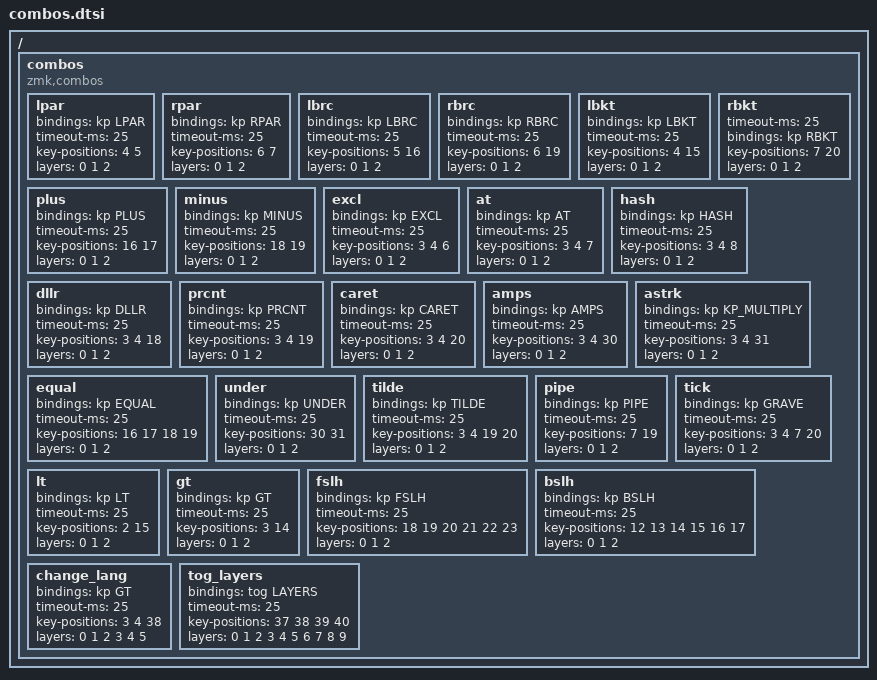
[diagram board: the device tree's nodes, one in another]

/ {
  combos {
    compatible = "zmk,combos";

    /* Basic combos */
    lpar {
      bindings = <&kp LPAR>;
      timeout-ms = <25>;
      key-positions = <4 5>;
      layers = <0 1 2>;
    };

    rpar {
      bindings = <&kp RPAR>;
      timeout-ms = <25>;
      key-positions = <6 7>;
      layers = <0 1 2>;
    };

    lbrc {
      bindings = <&kp LBRC>;
      timeout-ms = <25>;
      key-positions = <5 16>;
      layers = <0 1 2>;
    };

    rbrc {
      bindings = <&kp RBRC>;
      timeout-ms = <25>;
      key-positions = <6 19>;
      layers = <0 1 2>;
    };

    lbkt {
      bindings = <&kp LBKT>;
      timeout-ms = <25>;
      key-positions = <4 15>;
      layers = <0 1 2>;
    };

    rbkt {
      timeout-ms = <25>;
      bindings = <&kp RBKT>;
      key-positions = <7 20>;
      layers = <0 1 2>;
    };

    plus  {
      bindings = <&kp PLUS>;
      timeout-ms = <25>;
      key-positions = <16 17>;
      layers = <0 1 2>;
    };

    minus {
      bindings = <&kp MINUS>;
      timeout-ms = <25>;
      key-positions = <18 19>;
      layers = <0 1 2>;

    };

    excl  {
      bindings = <&kp EXCL>;
      timeout-ms = <25>;
      key-positions = <3 4 6>;
      layers = <0 1 2>;
    };

    at    {
      bindings = <&kp AT>;
      timeout-ms = <25>;
      key-positions = <3 4 7>;
      layers = <0 1 2>;
    };

    hash  {
      bindings = <&kp HASH>;
      timeout-ms = <25>;
      key-positions = <3 4 8>;
      layers = <0 1 2>;
    };

    dllr  {
      bindings = <&kp DLLR>;
      timeout-ms = <25>;
      key-positions = <3 4 18>;
      layers = <0 1 2>;
    };

    prcnt {
      bindings = <&kp PRCNT>;
      timeout-ms = <25>;
      key-positions = <3 4 19>;
      layers = <0 1 2>;
    };

    caret {
      bindings = <&kp CARET>;
      timeout-ms = <25>;
      key-positions = <3 4 20>;
      layers = <0 1 2>;
    };

    amps  {
      bindings = <&kp AMPS>;
      timeout-ms = <25>;
      key-positions = <3 4 30>;
      layers = <0 1 2>;
    };

    astrk {
      bindings = <&kp KP_MULTIPLY>;
      timeout-ms = <25>;
      key-positions = <3 4 31>;
      layers = <0 1 2>;
    };

    equal {
      bindings = <&kp EQUAL>;
      timeout-ms = <25>;
      key-positions = <16 17 18 19>;
      layers = <0 1 2>;
    };

    under {
      bindings = <&kp UNDER>;
      timeout-ms = <25>;
      key-positions = <30 31>;
      layers = <0 1 2>;
    };

    tilde {
      bindings = <&kp TILDE>;
      timeout-ms = <25>;
      key-positions = <3 4 19 20>;
      layers = <0 1 2>;
    };

    pipe {
      bindings = <&kp PIPE>;
      timeout-ms = <25>;
      key-positions = <7 19>;
      layers = <0 1 2>;
    };

    tick {
      bindings = <&kp GRAVE>;
      timeout-ms = <25>;
      key-positions = <3 4 7 20>;
      layers = <0 1 2>;
    };

    lt {
      bindings = <&kp LT>;
      timeout-ms = <25>;
      key-positions = <2 15>;
      layers = <0 1 2>;
    };

    gt {
      bindings = <&kp GT>;
      timeout-ms = <25>;
      key-positions = <3 14>;
      layers = <0 1 2>;
    };

    /* In Test Mode */
    fslh {
      bindings = <&kp FSLH>;
      timeout-ms = <25>;
      key-positions = <18 19 20 21 22 23>;
      layers = <0 1 2>;
    };

    bslh {
      bindings = <&kp BSLH>;
      timeout-ms = <25>;
      key-positions = <12 13 14 15 16 17>;
      layers = <0 1 2>;
    };

    /* Custom Combos */
    change_lang {
      bindings = <&kp GT>;
      timeout-ms = <25>;
      key-positions = <3 4 38>;
      layers = <0 1 2 3 4 5>;
    };

    tog_layers {
      bindings = <&tog LAYERS>;
      timeout-ms = <25>;
      key-positions = <37 38 39 40>;
      layers = <0 1 2 3 4 5 6 7 8 9>;
    };
  };
};
